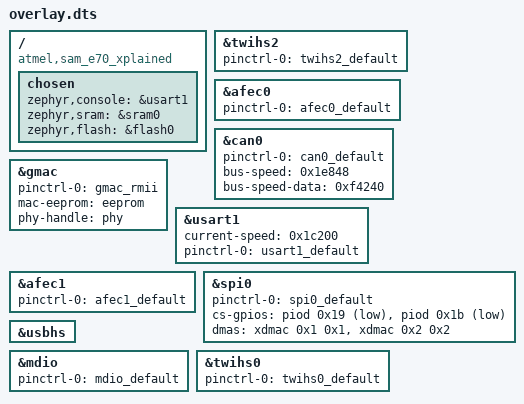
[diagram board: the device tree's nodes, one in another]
/ {
	compatible = "atmel,sam_e70_xplained", "atmel,same70q21", "atmel,same70";
	chosen {
		zephyr,console = &usart1;
		zephyr,sram = &sram0;
		zephyr,flash = &flash0;
	};
};
&twihs2{
	status = "okay";
	pinctrl-0 = < &twihs2_default >;
	pinctrl-names = "default";
};
&afec0{
	status = "okay";
	pinctrl-0 = < &afec0_default >;
	pinctrl-names = "default";
};
&can0{
	status = "okay";
	pinctrl-0 = < &can0_default >;
	pinctrl-names = "default";
	bus-speed = < 0x1e848 >;
	bus-speed-data = < 0xf4240 >;
};
&gmac{
	status = "okay";
	pinctrl-0 = < &gmac_rmii >;
	pinctrl-names = "default";
	mac-eeprom = < &eeprom >;
	phy-handle = < &phy >;
};
&usart1{
	status = "okay";
	current-speed = < 0x1c200 >;
	pinctrl-0 = < &usart1_default >;
	pinctrl-names = "default";
};
&afec1{
	status = "okay";
	pinctrl-0 = < &afec1_default >;
	pinctrl-names = "default";
};
&spi0{
	status = "okay";
	pinctrl-0 = < &spi0_default >;
	pinctrl-names = "default";
	cs-gpios = < &piod 0x19 0x1 >, < &piod 0x1b 0x1 >;
	dmas = < &xdmac 0x1 0x1 >, < &xdmac 0x2 0x2 >;
	dma-names = "tx", "rx";
};
&usbhs{
	status = "okay";
};
&mdio{
	status = "okay";
	pinctrl-0 = < &mdio_default >;
	pinctrl-names = "default";
};
&twihs0{
	status = "okay";
	pinctrl-0 = < &twihs0_default >;
	pinctrl-names = "default";
};
